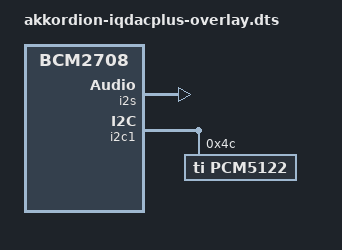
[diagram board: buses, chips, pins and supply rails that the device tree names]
// Definitions for Digital Dreamtime Akkordion using IQaudIO DAC+ or DACZero
/dts-v1/;
/plugin/;

/ {
	compatible = "brcm,bcm2708";

	fragment@0 {
		target = <&sound>;
		frag0: __overlay__ {
			compatible = "iqaudio,iqaudio-dac";
			card_name = "Akkordion";
			dai_name = "IQaudIO DAC";
			dai_stream_name = "IQaudIO DAC HiFi";
			i2s-controller = <&i2s>;
			status = "okay";
		};
	};

	fragment@1 {
		target = <&i2s>;
		__overlay__ {
			status = "okay";
		};
	};

	fragment@2 {
		target = <&i2c1>;
		__overlay__ {
			#address-cells = <1>;
			#size-cells = <0>;
			status = "okay";

			pcm5122@4c {
				#sound-dai-cells = <0>;
				compatible = "ti,pcm5122";
				reg = <0x4c>;
				status = "okay";
			};
		};
	};

	__overrides__ {
		24db_digital_gain = <&frag0>,"iqaudio,24db_digital_gain?";
	};
};
